# LPC804 register map
Vendor: nxp.com; File version: 1.0
CPU: CM0PLUS r0p0, little endian, no MPU, no FPU, VTOR, 2 interrupt priority bits
Registers are 32-bit, read-write, reset 0x0 unless marked. A register's access mark holds for its fields unless they carry their own. Offsets are from the block's base; [hi:lo] are bit positions; lines under a group give offsets from that group; {n}, {i} and the like mark numbered series; 'fields as' and 'values as' point back to an identical list.

## SYSCON — LPC80X System configuration (SYSCON)
Base 0x40048000
0x00 SYSMEMREMAP reset 0x2 — System Remap register
  [1:0] MAP — System memory remap. Value 0x2 is reserved.
    0=BOOT_LOADER_MODE (Boot Loader Mode. Interrupt vectors are re-mapped to Boot ROM.); 1=USER_RAM_MODE (User RAM Mode. Interrupt vectors are re-mapped to Static RAM.); 2=USER_FLASH_MODE (User Flash Mode. Interrupt vectors are not re-mapped and reside in Flash.)
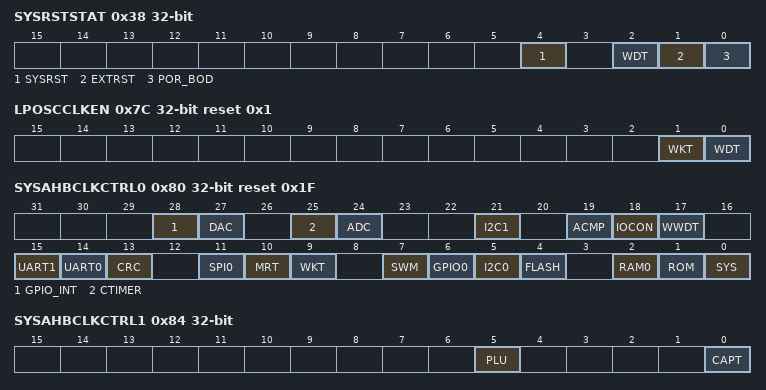
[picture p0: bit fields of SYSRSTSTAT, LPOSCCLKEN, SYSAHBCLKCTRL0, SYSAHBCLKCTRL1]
0x38 SYSRSTSTAT — System reset status register.
  [4] SYSRST — Status of the software system reset.
  [2] WDT — Status of the Watchdog reset.
  [1] EXTRST — Status of the external RESET pin
  [0] POR_BOD — POR and BOD reset status
0x50 MAINCLKSEL — Main clock source select register
  [1:0] SEL — Clock source for main clock.
    0=FRO; 1=EXT_CLK (External clock.); 2=WDTOSC (Low power oscillator.); 3=FRO_DIV
0x54 MAINCLKUEN — Main clock source update enable register.
  [0] ENA — Enable main clock source update
    0=NO_CHANGE; 1=UPDATED (update clock source)
0x58 SYSAHBCLKDIV reset 0x1 — System clock divider register
  [7:0] DIV — System AHB clock divider values 0: System clock disabled. 1: Divide by 1. to 255: Divide by 255.
0x60 CAPTCLKSEL reset 0x7 — Capacitive Touch clock source select.
  [2:0] SEL — Peripheral clock source.
    0=FRO; 1=Main_clock; 3=FRO_DIV (FRO_DIV = FRO/2); 4=Low_power_oscillator; 7=None
0x64 ADCCLKSEL — ADC clock source select register
  [1:0] SEL — Clock source for ADC clock
    0=FRO; 1=External_clock; 3=None
0x68 ADCCLKDIV — ADC clock divider register
  [7:0] DIV — ADC clock divider values 0: ADC clock disabled. 1: Divide by 1. to 255: Divide by 255.
0x7C LPOSCCLKEN reset 0x1 — WDT and Wake Timer clock enable control.
  [1] WKT — Enables clock for Wake Timer
    0=Disable; 1=Enable
  [0] WDT — Enables clock for WDT
    0=Disable; 1=Enable
0x80 SYSAHBCLKCTRL0 reset 0x1F — System clock group 0 control register
  [28] GPIO_INT — Enable clock for GPIO pin interrupt registers
    0=DISABLE; 1=ENABLE
  [27] DAC — Enables clock for DAC.
    0=DISABLE; 1=ENABLE
  [25] CTIMER — Enables clock for CTIMER.
    0=DISABLE; 1=ENABLE
  [24] ADC — Enables clock for ADC.
    0=DISABLE; 1=ENABLE
  [21] I2C1 — Enables clock for I2C1.
    0=DISABLE; 1=ENABLE
  [19] ACMP — Enables clock for analog comparator.
    0=DISABLE; 1=ENABLE
  [18] IOCON — Enables clock for IOCON.
    0=DISABLE; 1=ENABLE
  [17] WWDT — Enables clock for WWDT.
    0=DISABLE; 1=ENABLE
  [15] UART1 — Enables clock for UART1.
    0=DISABLE; 1=ENABLE
  [14] UART0 — Enables clock for UART0.
    0=DISABLE; 1=ENABLE
  [13] CRC — Enables clock for CRC.
    0=DISABLE; 1=ENABLE
  [11] SPI0 — Enables clock for SPI0.
    0=DISABLE; 1=ENABLE
  [10] MRT — Enables clock for multi-rate timer.
    0=DISABLE; 1=ENABLE
  [9] WKT — Enables clock for self-wake-up timer.
    0=DISABLE; 1=ENABLE
  [7] SWM — Enables clock for switch matrix.
    0=DISABLE; 1=ENABLE
  [6] GPIO0 — Enables clock for GPIO0 port registers.
    0=DISABLE; 1=ENABLE
  [5] I2C0 — Enables clock for I2C0.
    0=DISABLE; 1=ENABLE
  [4] FLASH — Enables clock for flash.
    0=DISABLE; 1=ENABLE
  [2] RAM0 — Enables clock for SRAM0
    0=DISABLE; 1=ENABLE
  [1] ROM — Enables clock for ROM.
    0=DISABLE; 1=ENABLE
  [0] SYS — Enables the clock for the AHB, the APB bridge, the Cortex-M0+ core clocks, SYSCON, and the PMU. This bit is read only and always reads as 1.
0x84 SYSAHBCLKCTRL1 — System clock group 1 control register
  [5] PLU — Enables clock for PLU.
    0=DISABLE; 1=ENABLE
  [0] CAPT — Enables the clock for Capacitive Touch.
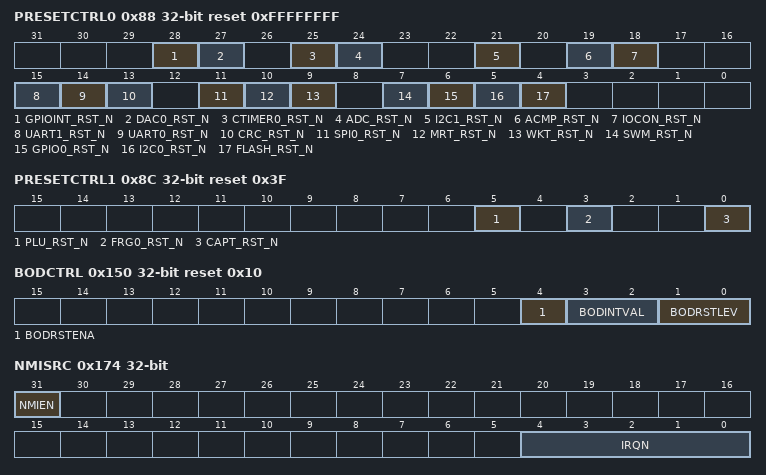
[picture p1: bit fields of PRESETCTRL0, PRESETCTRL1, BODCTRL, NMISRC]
0x88 PRESETCTRL0 reset 0xFFFFFFFF — Peripheral reset group 0 control register
  [28] GPIOINT_RST_N — GPIOINT reset control
    0=ASSERT (Assert the GPIOINT reset.); 1=CLEAR (Clear the GPIOINT reset.)
  [27] DAC0_RST_N — DAC0 reset control.
    0=ASSERT (Assert the DAC0 reset.); 1=CLEAR (Clear the DAC0 reset.)
  [25] CTIMER0_RST_N — CTIMER reset control
    0=ASSERT (Assert the CTIMER reset.); 1=CLEAR (Clear the CTIMER reset.)
  [24] ADC_RST_N — ADC reset control
    0=ASSERT (Assert the ADC reset.); 1=CLEAR (Clear the ADC reset.)
  [21] I2C1_RST_N — I2C1 reset control.
    0=ASSERT (Assert the I2C1 reset.); 1=CLEAR (Clear the I2C1 reset.)
  [19] ACMP_RST_N — Analog comparator reset control
    0=ASSERT (Assert the analog comparator reset.); 1=CLEAR (Clear the analog comparator reset.)
  [18] IOCON_RST_N — IOCON reset control
    0=ASSERT (Assert the IOCON reset.); 1=CLEAR (Clear the IOCON reset.)
  [15] UART1_RST_N — UART1 reset control
    0=ASSERT (Assert the UART1 reset.); 1=CLEAR (Clear the UART1 reset.)
  [14] UART0_RST_N — UART0 reset control
    0=ASSERT (Assert the UART0 reset.); 1=Clear the UART0 reset
  [13] CRC_RST_N — CRC engine reset control
    0=ASSERT (Assert the CRC reset.); 1=CLEAR (Clear the CRC reset.)
  [11] SPI0_RST_N — SPI0 reset control
    0=ASSERT (Assert the SPI0 reset.); 1=CLEAR (Clear the SPI0 reset.)
  [10] MRT_RST_N — Multi-rate timer (MRT) reset control
    0=ASSERT (Assert the MRT reset.); 1=CLEAR (Clear the MRT reset.)
  [9] WKT_RST_N — Self-wake-up timer (WKT) reset control
    0=ASSERT (Assert the WKT reset.); 1=CLEAR (Clear the WKT reset.)
  [7] SWM_RST_N — SWM reset control
    0=ASSERT (Assert the SWM reset.); 1=CLEAR (Clear the SWM reset.)
  [6] GPIO0_RST_N — GPIO0 reset control
    0=ASSERT (Assert the GPIO0 reset.); 1=CLEAR (Clear the GPIO0 reset.)
  [5] I2C0_RST_N — I2C0 reset control
    0=ASSERT (Assert the I2C0 reset.); 1=CLEAR (Clear the I2C0 reset.)
  [4] FLASH_RST_N — flash controller reset control
    0=ASSERT (Assert the flash controller reset.); 1=CLEAR (Clear the flash controller reset.)
0x8C PRESETCTRL1 reset 0x3F — Peripheral reset group 1 control register
  [5] PLU_RST_N — PLU reset control.
    0=ASSERT (Assert PLU reset.); 1=CLEAR (Clear PLU reset.)
  [3] FRG0_RST_N — Fractional baud rate generator 0 reset control
    0=ASSERT (Assert the FRG0 reset.); 1=CLEAR (Clear the FRG0 reset.)
  [0] CAPT_RST_N — Capacitive Touch reset control.
    0=ASSERT (Assert Capacitive Touch reset.); 1=CLEAR (Clear Capacitive Touch reset.)
0x90 UART0CLKSEL reset 0x7 — Function clock source select for UART0.
  [2:0] SEL — Peripheral clock source
    0=FRO; 1=MAIN_CLK (main clock); 2=FRO0CLK (Frg0clk); 3=NONE; 4=FRO_DIV; 5=NONE1; 6=NONE2; 7=NONE3
0x94 UART1CLKSEL reset 0x7 — Function clock source select for UART1.
  fields as UART0CLKSEL
0xA4 I2C0CLKSEL reset 0x7 — Function clock source select for I2C0.
  fields as UART0CLKSEL
0xA8 I2C1CLKSEL reset 0x7 — Function clock source select for I2C1.
  fields as UART0CLKSEL
0xB4 SPI0CLKSEL reset 0x7 — Function clock source select for SPI0.
  fields as UART0CLKSEL
0xD0 FRG0DIV — fractional generator divider value register
  [7:0] DIV — Denominator of the fractional divider. DIV is equal to the programmed value +1. Always set to 0xFF to use with the fractional baud rate generator.
0xD4 FRG0MULT — fractional generator multiplier value register
  [7:0] MULT — Numerator of the fractional divider. MULT is equal to the programmed value.
0xD8 FRG0CLKSEL — FRG clock source select register
  [1:0] SEL — Clock source for frgN_src clock
    0=FRO; 1=MAIN_CLK (main clock); 3=NONE
0xF0 CLKOUTSEL — CLKOUT clock source select register
  [2:0] SEL — CLKOUT clock source
    0=FRO; 1=MAIN_CLK (main clock); 3=EXT_CLK (external clock); 4=Low_power_oscillator; 7=None
0xF4 CLKOUTDIV — CLKOUT clock divider registers
  [7:0] DIV — CLKOUT clock divider values 0: Disable CLKOUT clock divider. 1: Divide by 1. to 255: Divide by 255.
0x100 PIOPORACP reset not defined — POR captured PIO0 status 0
  [31:0] PIOSTAT — State of PIO0_0 to PIO0_5 and PIO0_7 to PIO0_17 at power-on reset
0x150 BODCTRL reset 0x10 — BOD control register
  [4] BODRSTENA — BOD reset enable
    0=DISABLE (Disable reset function.); 1=ENABLE (Enable reset function.)
  [3:2] BODINTVAL — BOD interrupt level
    1=LEVEL_1; 2=LEVEL_2; 3=LEVEL_3
  [1:0] BODRSTLEV — BOD reset level
    1=LEVEL_1; 2=LEVEL_2; 3=LEVEL_3
0x154 SYSTCKCAL — System tick timer calibration register
  [25:0] CAL — System tick timer calibration value.
0x170 IRQLATENCY reset 0x10
  [7:0] LATENCY — 8-bit latency value.
0x174 NMISRC — NMI source selection register
  [31] NMIEN — Write a 1 to this bit to enable the Non-Maskable Interrupt (NMI) source selected by bits 4:0.
  [4:0] IRQN — The IRQ number of the interrupt that acts as the Non-Maskable Interrupt (NMI) if bit 31 is 1
{0x178+4i} PINTSEL[{i}] (i=0..7) — Pin interrupt select registers N
  [5:0] INTPIN — Pin number select for pin interrupt or pattern match engine input. (PIO0_0 to PIO0_5 correspond to numbers 0 to 5. PIO0_7 to PIO0_30 correspond to numbers 7 to 30.)
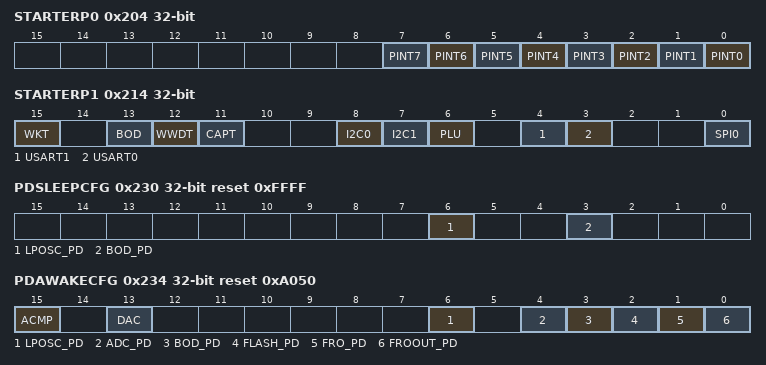
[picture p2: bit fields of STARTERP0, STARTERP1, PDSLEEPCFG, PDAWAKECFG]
0x204 STARTERP0 — Start logic 0 pin wake-up enable register 0
  [all] fields
    0=DISABLED; 1=ENABLED
  [n] PINT{n} (n=0..7) — GPIO pin interrupt {n} wake-up
0x214 STARTERP1 — Start logic 0 pin wake-up enable register 1
  [all] fields
    0=DISABLED; 1=ENABLED
  [15] WKT — Self-wake-up timer interrupt wake-up
  [13] BOD — BOD interrupt wake-up
  [12] WWDT — WWDT interrupt wake-up
  [11] CAPT — CAPT interrupt wake-up.
  [8] I2C0 — I2C0 interrupt wake-up.
  [7] I2C1 — I2C1 interrupt wake-up.
  [6] PLU — PLU interrupt wake-up.
  [4] USART1 — USART1 interrupt wake-up. Configure USART in synchronous slave mode.
  [3] USART0 — USART0 interrupt wake-up. Configure USART in synchronous slave mode.
  [0] SPI0 — SPI0 interrupt wake-up
0x230 PDSLEEPCFG reset 0xFFFF — Deep-sleep configuration register
  [6] LPOSC_PD — Low power oscillator power-down control for deep-sleep and power-down mode. Changing this bit to powered-down has no effect when the LOCK bit in the WWDT MOD register is set. In this case, the low power oscillator is always running.
    0=DISABLED; 1=ENABLED
  [3] BOD_PD — BOD power-down control for Deep-sleep and Power-down mode
    0=POWERED; 1=POWERED_DOWN
0x234 PDAWAKECFG reset 0xA050 — Wake-up configuration register
  [15] ACMP — Analog comparator wake-up configuration
    0=DISABLED; 1=ENABLED
  [13] DAC — DAC0 wake-up configuration.
    0=DISABLED; 1=ENABLED
  [6] LPOSC_PD — Low power oscillator wake-up configuration. Changing this bit to powered-down has no effect when the LOCK bit in the WWDT MOD register is set. In this case, the low power oscillator is always running.
    0=DISABLED; 1=ENABLED
  [4] ADC_PD — ADC wake-up configuration
    0=POWERED; 1=POWERED_DOWN
  [3] BOD_PD — BOD wake-up configuration
    0=POWERED; 1=POWERED_DOWN
  [2] FLASH_PD — Flash wake-up configuration
    0=POWERED; 1=POWERED_DOWN
  [1] FRO_PD — FRO oscillator power-down wake-up configuration
    0=POWERED; 1=POWERED_DOWN
  [0] FROOUT_PD — FRO oscillator output wake-up configuration
    0=POWERED; 1=POWERED_DOWN
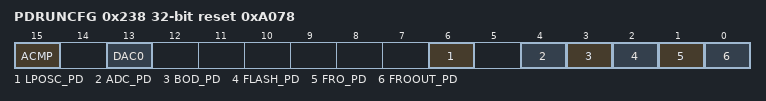
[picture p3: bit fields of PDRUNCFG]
0x238 PDRUNCFG reset 0xA078 — Power configuration register
  [15] ACMP — Analog comparator wake-up configuration
    0=DISABLED; 1=ENABLED
  [13] DAC0 — DAC0 wake-up configuration.
    0=DISABLED; 1=ENABLED
  [6] LPOSC_PD — Low power oscillator power down. Changing this bit to powered-down has no effect when the LOCK bit in the WWDT MOD register is set. In this case, the low power oscillator is always running.
    0=DISABLED; 1=ENABLED
  [4] ADC_PD — ADC wake-up configuration
    0=POWERED; 1=POWERED_DOWN
  [3] BOD_PD — BOD wake-up configuration
    0=POWERED; 1=POWERED_DOWN
  [2] FLASH_PD — Flash wake-up configuration
    0=POWERED; 1=POWERED_DOWN
  [1] FRO_PD — FRO oscillator power-down wake-up configuration
    0=POWERED; 1=POWERED_DOWN
  [0] FROOUT_PD — FRO oscillator output wake-up configuration
    0=POWERED; 1=POWERED_DOWN
0x3F8 DEVICE_ID ro reset not defined
  [31:0] DEVICEID — Used to read the part identification number.
